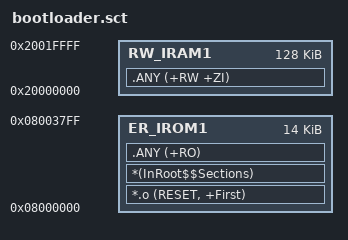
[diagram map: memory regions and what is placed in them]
; *************************************************************
; *** Scatter-Loading Description File for AT32F456 Bootloader ***
; *************************************************************
; Bootloader: 0x08000000 - 0x08003800 (14KB)
; App Header: 0x08003800 - 0x08004000 (2KB, managed by bootloader at runtime)
; App Start: 0x08004000
; *************************************************************

LR_IROM1 0x08000000 0x00003800  {    ; Bootloader load region 14KB
  ER_IROM1 0x08000000 0x00003800  {  ; Bootloader execution region
   *.o (RESET, +First)
   *(InRoot$$Sections)
   .ANY (+RO)
  }
  RW_IRAM1 0x20000000 0x00020000  {  ; SRAM 128KB
   .ANY (+RW +ZI)
  }
}
